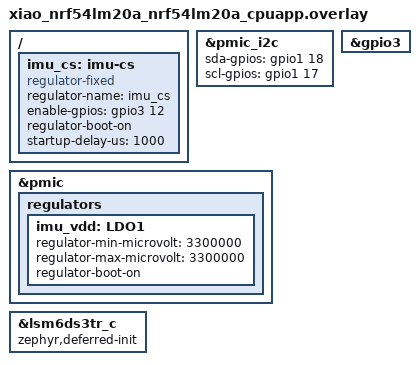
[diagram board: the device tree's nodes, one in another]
&pmic_i2c {
	sda-gpios = <&gpio1 18 GPIO_ACTIVE_HIGH>;
	scl-gpios = <&gpio1 17 GPIO_ACTIVE_HIGH>;
	status = "okay";
};

&pmic {
	regulators {
		imu_vdd: LDO1 {
			regulator-min-microvolt = <3300000>;
			regulator-max-microvolt = <3300000>;
			regulator-boot-on;
		};
	};
};

&gpio3 {
	status = "okay";
};

/ {
	imu_cs: imu-cs {
		compatible = "regulator-fixed";
		regulator-name = "imu_cs";
		enable-gpios = <&gpio3 12 GPIO_ACTIVE_HIGH>;
		regulator-boot-on;
		startup-delay-us = <1000>;
	};
};

&lsm6ds3tr_c {
	zephyr,deferred-init;
};
